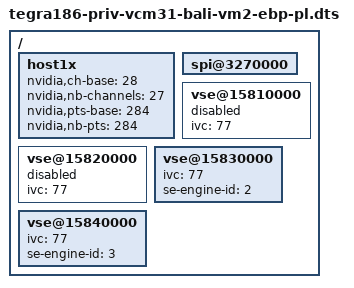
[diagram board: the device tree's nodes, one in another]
/*
 * tegra186-priv-vcm31-bali-vm2-ebp.dts: bali vm2 ebp dts
 * file
 *
 * Copyright (c) 2015 - 2016, NVIDIA CORPORATION.  All rights reserved.
 *
 * This program is free software; you can redistribute it and/or modify
 * it under the terms of the GNU General Public License as published by
 * the Free Software Foundation; version 2 of the License.
 *
 * This program is distributed in the hope that it will be useful, but WITHOUT
 * ANY WARRANTY; without even the implied warranty of MERCHANTABILITY or
 * FITNESS FOR A PARTICULAR PURPOSE.  See the GNU General Public License for
 * more details.
 */

#include "tegra186-priv-vcm31-bali-vm2-ebp.dts"

/ {
	host1x: host1x {
		nvidia,ch-base = <28>;
		nvidia,nb-channels = <27>;
		nvidia,pts-base = <284>;
		nvidia,nb-pts = <284>;
	};

	spi@3270000 {
		status = "okay";
	};

	vse@15810000 {
		ivc = <77>;
		status = "disabled";
	};

	vse@15820000 {
		ivc = <77>;
		status = "disabled";
	};

	vse@15830000 {
		ivc = <77>;
		se-engine-id = <2>;
	};

	vse@15840000 {
		ivc = <77>;
		se-engine-id = <3>;
	};
};
